# PY32F002Bxx register map
Vendor: Puya; Series: PY32F0; File version: 1.0.0
CPU: CM0+ r0p1, little endian, no MPU, no FPU, 4 interrupt priority bits
Registers are 32-bit, read-write, reset 0x0 unless marked. A register's access mark holds for its fields unless they carry their own. Offsets are from the block's base; [hi:lo] are bit positions; 'fields as' and 'values as' point back to an identical list.

## SPI1 — Serial peripheral interface
Base 0x40013000
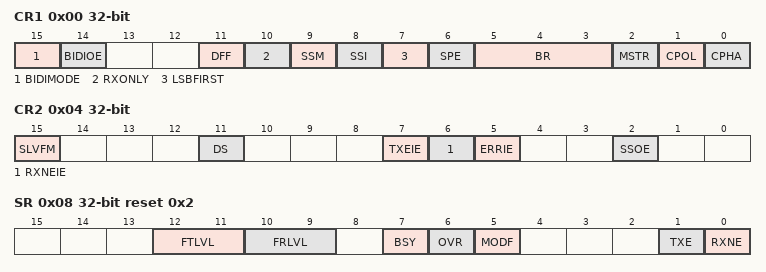
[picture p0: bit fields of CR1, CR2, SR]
0x00 CR1
  [15] BIDIMODE
    0=Unidirectional (2-line unidirectional data mode selected); 1=Bidirectional (1-line bidirectional data mode selected)
  [14] BIDIOE
    0=Output disabled (receive-only mode); 1=Output enabled (transmit-only mode)
  [11] DFF
  [10] RXONLY
    0=Full duplex (Transmit and receive); 1=Output disabled (Receive-only mode)
  [9] SSM
    0=Disabled (Software slave management disabled); 1=Enabled (Software slave management enabled)
  [8] SSI
    0=SlaveSelected (0 is forced onto the NSS pin and the I/O value of the NSS pin is ignored); 1=SlaveNotSelected (1 is forced onto the NSS pin and the I/O value of the NSS pin is ignored)
  [7] LSBFIRST
    0=MSBFirst (Data is transmitted/received with the MSB first); 1=LSBFirst (Data is transmitted/received with the LSB first)
  [6] SPE
    0=Disabled (Peripheral disabled); 1=Enabled (Peripheral enabled)
  [5:3] BR
    0=Div2 (f_PCLK / 2); 1=Div4 (f_PCLK / 4); 2=Div8 (f_PCLK / 8); 3=Div16 (f_PCLK / 16); 4=Div32 (f_PCLK / 32); 5=Div64 (f_PCLK / 64); 6=Div128 (f_PCLK / 128); 7=Div256 (f_PCLK / 256)
  [2] MSTR
    0=Slave configuration; 1=Master configuration
  [1] CPOL
    0=IdleLow (CK to 0 when idle); 1=IdleHigh (CK to 1 when idle)
  [0] CPHA
    0=FirstEdge (The first clock transition is the first data capture edge); 1=SecondEdge (The second clock transition is the first data capture edge)
0x04 CR2
  [15] SLVFM
    0=Normal (Slave normal mode, spi clock speed less than PCLK / 4); 1=Fast (Slave fast mode, spi clock speed equal to PCLK / 4)
  [11] DS
    0=EightBit (8-bit); 1=SixteenBit (16-bit)
  [7] TXEIE
    0=Masked (TXE interrupt masked); 1=NotMasked (TXE interrupt not masked)
  [6] RXNEIE
    0=Masked (RXE interrupt masked); 1=NotMasked (RXE interrupt not masked)
  [5] ERRIE
    0=Masked (Error interrupt masked); 1=NotMasked (Error interrupt not masked)
  [2] SSOE
    0=Disabled (SS output is disabled in master mode); 1=Enabled (SS output is enabled in master mode)
0x08 SR reset 0x2
  [12:11] FTLVL ro
    0=Empty (Tx FIFO Empty); 1=Quarter (Tx 1/4 FIFO); 2=Half (Tx 1/2 FIFO); 3=Full (Tx FIFO full)
  [10:9] FRLVL ro
    0=Empty (Rx FIFO Empty); 1=Quarter (Rx 1/4 FIFO); 2=Half (Rx 1/2 FIFO); 3=Full (Rx FIFO full)
  [7] BSY ro
    0=NotBusy (SPI not busy); 1=Busy (SPI busy)
  [6] OVR ro
    0=No overrun occurred; 1=Overrun occurred
  [5] MODF ro
    0=NoFault (No mode fault occurred); 1=Fault (Mode fault occurred)
  [1] TXE ro
    0=NotEmpty (Tx buffer not empty); 1=Empty (Tx buffer empty)
  [0] RXNE ro
    0=Empty (Rx buffer empty); 1=NotEmpty (Rx buffer not empty)
0x0C DR
  [15:0] DR
0x0C DR8 8-bit (alternate view of DR) — Direct 8-bit access to data register
  [7:0] DR — Data register

## DBG — Debug support
Base 0x40015800
0x00 IDCODE ro — MCU Device ID Code Register
  [31:0] CODE — DBG ID code register
0x04 CR — Debug MCU Configuration Register
  [1] DBG_STOP — Debug Stop Mode
    0=Disabled (Debug Stop Mode Disabled); 1=Enabled (Debug Stop Mode Enabled)
0x08 APB_FZ1 — APB Freeze Register1
  [31] DBG_LPTIM_STOP — Debug LPTIM stopped when Core ishalted
    0=Continue (LPTIMx counter clock is fed even if the core is halted); 1=Stop (LPTIMx counter clock is stopped when the core is halted)
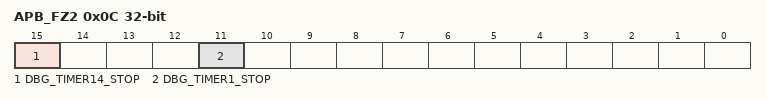
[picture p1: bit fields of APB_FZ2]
0x0C APB_FZ2 — APB Freeze Register2
  [15] DBG_TIMER14_STOP — Debug TIM 14 stopped whenCore is halted
    0=Continue (The counter clock of TIMx is fed even if the core is halted); 1=Stop (The counter clock of TIMx is stopped when the core is halted)
  [11] DBG_TIMER1_STOP — Debug Timer 1 stopped when Core ishalted
    values as DBG_TIMER14_STOP
